AUTOSAR XML (schema 4-0-3)
package /ComponentTypes
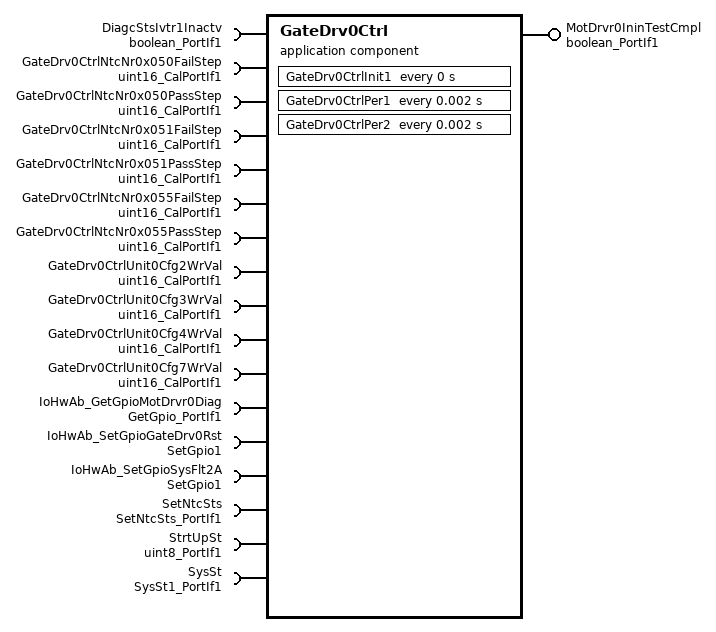
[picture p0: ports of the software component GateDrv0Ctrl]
  application sw component type GateDrv0Ctrl
    provide port MotDrvr0IninTestCmpl: nonqueued-sender-com-spec{data-element=Logl, init-value=0}, provided-interface=boolean_PortIf1
    17 x require port:
      DiagcStsIvtr1Inactv: nonqueued-receiver-com-spec{data-element=Logl, filter=data-filter-type=ALWAYS, init-value=0}, required-interface=boolean_PortIf1
      GateDrv0CtrlNtcNr0x050FailStep: parameter-require-com-spec{init-value=4096, parameter=Val}, required-interface=uint16_CalPortIf1
      GateDrv0CtrlNtcNr0x050PassStep: parameter-require-com-spec{init-value=4096, parameter=Val}, required-interface=uint16_CalPortIf1
      GateDrv0CtrlNtcNr0x051FailStep: parameter-require-com-spec{init-value=4096, parameter=Val}, required-interface=uint16_CalPortIf1
      GateDrv0CtrlNtcNr0x051PassStep: parameter-require-com-spec{init-value=4096, parameter=Val}, required-interface=uint16_CalPortIf1
      GateDrv0CtrlNtcNr0x055FailStep: parameter-require-com-spec{init-value=4096, parameter=Val}, required-interface=uint16_CalPortIf1
      GateDrv0CtrlNtcNr0x055PassStep: parameter-require-com-spec{init-value=4096, parameter=Val}, required-interface=uint16_CalPortIf1
      GateDrv0CtrlUnit0Cfg2WrVal: parameter-require-com-spec{init-value=2832, parameter=Val}, required-interface=uint16_CalPortIf1
      GateDrv0CtrlUnit0Cfg3WrVal: parameter-require-com-spec{init-value=3598, parameter=Val}, required-interface=uint16_CalPortIf1
      GateDrv0CtrlUnit0Cfg4WrVal: parameter-require-com-spec{init-value=4622, parameter=Val}, required-interface=uint16_CalPortIf1
      GateDrv0CtrlUnit0Cfg7WrVal: parameter-require-com-spec{init-value=7924, parameter=Val}, required-interface=uint16_CalPortIf1
      IoHwAb_GetGpioMotDrvr0Diag: required-interface=GetGpio_PortIf1
      IoHwAb_SetGpioGateDrv0Rst: required-interface=SetGpio1
      IoHwAb_SetGpioSysFlt2A: required-interface=SetGpio1
      SetNtcSts: required-interface=SetNtcSts_PortIf1
      StrtUpSt: nonqueued-receiver-com-spec{data-element=Val, filter=data-filter-type=ALWAYS, init-value=0}, required-interface=uint8_PortIf1
      SysSt: nonqueued-receiver-com-spec{data-element=Val, filter=data-filter-type=ALWAYS, init-value=3}, required-interface=SysSt1_PortIf1
    behavior GateDrv0Ctrl_InternalBehavior
      ar-typed-per-instance-memorys:
        22 x data, all with sw-calibration-access=READ-ONLY:
          dGateDrv0CtrlGateDrv0Diag{0..2}Val: type=uint16
          dGateDrv0CtrlGateDrv0OffsStVrfyPrmBitIdx: type=uint8
          dGateDrv0CtrlGateDrv0StsVal: type=uint16
          dGateDrv0CtrlGateDrv0VrfyRes0Val: type=uint16
          dGateDrv0CtrlGateDrv0VrfyRes1Val: type=uint16
          GateDrv0CfgCnt: type=uint8
          GateDrv0CfgSecAtmpt: type=boolean
          GateDrv0Diag{0..2}Val: type=uint16
          GateDrv0OffStChkIdx: type=uint8
          GateDrv0OffStChkSecAtmpt: type=boolean
          GateDrv0OffStCnt: type=uint8
          GateDrv0St: type=uint8
          GateDrv0StsVal: type=uint16
          GateDrv0VrfyRes0Val: type=uint16
          GateDrv0VrfyRes1Val: type=uint16
          Ivtr0BootstrpSplyFltPrmVal: type=uint8
          Ivtr0GenericFltPrmVal: type=uint8
          Ivtr0OffStChkCmpl: type=boolean
      timing event GateDrvCtrl_InitEvent: start-on-event=GateDrv0CtrlInit1, period=0
      timing event TMT_GateDrvCtrlPer1: start-on-event=GateDrv0CtrlPer1, period=0.002
      timing event TMT_GateDrv0CtrlPer2: start-on-event=GateDrv0CtrlPer2, period=0.002
      explicit-inter-runnable-variables:
        data GateDrv0Ena: type=boolean, init-value=0
        data Ivtr0PhyFltInpActv: type=boolean, init-value=0
      runnable GateDrv0CtrlInit1
      runnable GateDrv0CtrlPer1
        data-receive-point-by-arguments:
          access REC_DiagcStsIvtr1Inactv_Logl: accessed-variable=DiagcStsIvtr1Inactv.Logl
          access REC_StrtUpSt_Val: accessed-variable=StrtUpSt.Val
          access REC_SysSt_Val: accessed-variable=SysSt.Val
        sync call SC_IoHwAb_GetGpioMotDrvr0Diag_Oper: operation=IoHwAb_GetGpioMotDrvr0Diag.Oper, timeout=0
        sync call SC_IoHwAb_SetGpioGateDrv0Rst_Oper: operation=IoHwAb_SetGpioGateDrv0Rst.Oper, timeout=0
        written-local-variables:
          access WRITE_GateDrv0Ena: accessed-variable=GateDrv0Ena
          access WRITE_Ivtr0PhyFltInpActv: accessed-variable=Ivtr0PhyFltInpActv
      runnable GateDrv0CtrlPer2
        data-receive-point-by-arguments:
          access REC_DiagcStsIvtr1Inactv_Logl: accessed-variable=DiagcStsIvtr1Inactv.Logl
        data-send-points:
          access SEND_MotDrvr0IninTestCmpl_Logl: accessed-variable=MotDrvr0IninTestCmpl.Logl
        read-local-variables:
          access READ_GateDrv0Ena: accessed-variable=GateDrv0Ena
          access READ_Ivtr0PhyFltInpActv: accessed-variable=Ivtr0PhyFltInpActv
        4 x sync call, all with timeout=0:
          SC_IoHwAb_GetGpioMotDrvr0Diag_Oper: operation=IoHwAb_GetGpioMotDrvr0Diag.Oper
          SC_IoHwAb_SetGpioGateDrv0Rst_Oper: operation=IoHwAb_SetGpioGateDrv0Rst.Oper
          SC_IoHwAb_SetGpioSysFlt2A_Oper: operation=IoHwAb_SetGpioSysFlt2A.Oper
          SC_SetNtcSts_Oper: operation=SetNtcSts.Oper
  swc implementation GateDrv0Ctrl_Implementation: behavior=GateDrv0Ctrl_InternalBehavior
    code-descriptors:
      code Default: artifact-descriptors=autosar-engineering-object={short-label=Default, category=SWSRC}
